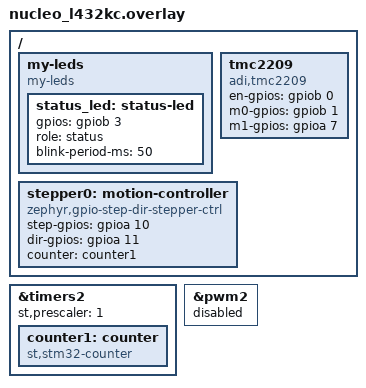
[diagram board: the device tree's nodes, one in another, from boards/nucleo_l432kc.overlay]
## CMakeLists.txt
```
#-------------------------------------------------------------------------------
# Zephyr Example Application (Rust)
#
# Copyright (c) 2021 Nordic Semiconductor ASA
# SPDX-License-Identifier: Apache-2.0
#
# The application is the Rust crate in this directory (Cargo.toml, src/*.rs),
# built and linked by the zephyr-lang-rust module. src/stepper_shim.c exposes
# the Zephyr stepper API, which the Rust bindings don't cover, to Rust.

cmake_minimum_required(VERSION 3.20.0)
find_package(Zephyr REQUIRED HINTS $ENV{ZEPHYR_BASE})

project(app LANGUAGES C)

rust_cargo_application()

target_sources(app PRIVATE src/stepper_shim.c)

# The code below locates the git index file for this repository and adds it as a dependency for
# the application VERSION file so that if the repo has a new commit added, even if no files in
# the build have changed, the application version file will be regenerated with the new git commit
find_package(Git QUIET)
if(GIT_FOUND)
  execute_process(
    COMMAND ${GIT_EXECUTABLE} rev-parse --absolute-git-dir
    WORKING_DIRECTORY .
    OUTPUT_VARIABLE application_git_dir
    OUTPUT_STRIP_TRAILING_WHITESPACE
    ERROR_STRIP_TRAILING_WHITESPACE
    ERROR_VARIABLE stderr
    RESULT_VARIABLE return_code
  )
  # If there is an error e.g. it is not a git repo, we just silently ignore it and continue
  # without a dependency, this will be the case with freestanding applications.
  if(NOT return_code)
    if(NOT "${stderr}" STREQUAL "")
      message(WARNING "Application build version git rev-parse warned: ${stderr}")
    endif()

    set_property(TARGET app_version_h PROPERTY APP_VERSION_DEPENDS ${application_git_dir}/index)
  endif()
endif()
```

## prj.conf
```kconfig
# Copyright (c) 2021 Nordic Semiconductor ASA
# SPDX-License-Identifier: Apache-2.0
#
# This file contains selected Kconfig options for the application.

CONFIG_CONSOLE=y
CONFIG_PRINTK=y
CONFIG_GPIO=y
CONFIG_COUNTER=y
CONFIG_STEPPER=y
CONFIG_COUNTER_TIMER_STM32=y

CONFIG_RUST=y
# The default 1k main stack isn't large enough for Rust's float formatting.
CONFIG_MAIN_STACK_SIZE=4096

CONFIG_NO_OPTIMIZATIONS=y
```

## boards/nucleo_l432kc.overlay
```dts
/{
    my-leds {
        compatible = "my-leds";

        /* LD3, the Nucleo's user LED */
        status_led: status-led {
            gpios = <&gpiob 3 GPIO_ACTIVE_HIGH>;
            role = "status";
            blink-period-ms = <50>;
        };
    };

    tmc2209: tmc2209 {
        compatible = "adi,tmc2209";
        en-gpios = <&gpiob 0 GPIO_ACTIVE_HIGH>;
        m0-gpios = <&gpiob 1 GPIO_ACTIVE_HIGH>;
        m1-gpios = <&gpioa 7 GPIO_ACTIVE_HIGH>;
        status = "okay";
    };

    stepper0: motion-controller {
        compatible = "zephyr,gpio-step-dir-stepper-ctrl";
        step-gpios = <&gpioa 10 GPIO_ACTIVE_HIGH>;
        dir-gpios = <&gpioa 11 GPIO_ACTIVE_HIGH>;
        counter = <&counter1>;

        // stepper-driver = <&tmc2209>;
        status = "okay";
    };
};

/* 1. Configure the STM32 Hardware Timer */
&timers2 {
    status = "okay";
    st,prescaler = <1>;

    /* Child node providing the counter API */
    counter1: counter {
        compatible = "st,stm32-counter";
        status = "okay";
    };
};

&pwm2 {
    status = "disabled";
};
```

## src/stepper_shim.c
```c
/*
 * SPDX-License-Identifier: Apache-2.0
 *
 * C entry points for the Zephyr stepper API, called from src/stepper.rs.
 *
 * The stepper API is made of static inline syscall wrappers, which Rust can't
 * link against directly, and zephyr-lang-rust doesn't generate bindings for it.
 * These functions give each call a real symbol with a plain C ABI.
 */

#include <stdbool.h>
#include <stdint.h>

#include <zephyr/device.h>
#include <zephyr/drivers/stepper/stepper.h>
#include <zephyr/drivers/stepper/stepper_ctrl.h>

const struct device *app_stepper0(void)
{
	return DEVICE_DT_GET(DT_NODELABEL(stepper0));
}

bool app_device_is_ready(const struct device *dev)
{
	return device_is_ready(dev);
}

int app_stepper_enable(const struct device *dev)
{
	return stepper_enable(dev);
}

int app_stepper_disable(const struct device *dev)
{
	return stepper_disable(dev);
}

int app_stepper_set_microstep_interval(const struct device *dev, uint64_t interval_ns)
{
	return stepper_ctrl_set_microstep_interval(dev, interval_ns);
}

int app_stepper_move_to(const struct device *dev, int32_t micro_steps)
{
	return stepper_ctrl_move_to(dev, micro_steps);
}

int app_stepper_move_by(const struct device *dev, int32_t micro_steps)
{
	return stepper_ctrl_move_by(dev, micro_steps);
}

int app_stepper_stop(const struct device *dev)
{
	return stepper_ctrl_stop(dev);
}

int app_stepper_is_moving(const struct device *dev, bool *is_moving)
{
	return stepper_ctrl_is_moving(dev, is_moving);
}

int app_stepper_get_actual_position(const struct device *dev, int32_t *position)
{
	return stepper_ctrl_get_actual_position(dev, position);
}

int app_stepper_set_reference_position(const struct device *dev, int32_t position)
{
	return stepper_ctrl_set_reference_position(dev, position);
}
```
